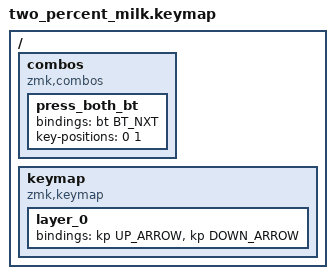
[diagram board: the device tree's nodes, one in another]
#include <behaviors.dtsi>
#include <dt-bindings/zmk/bt.h>
#include <dt-bindings/zmk/keys.h>

/ {
    combos {
        compatible = "zmk,combos";

        press_both_bt {
            bindings = <&bt BT_NXT>;
            key-positions = <0 1>;
        };
    };

    keymap {
        compatible = "zmk,keymap";

        layer_0 {
            bindings = <
&kp UP_ARROW  &kp DOWN_ARROW
            >;
        };
    };
};
